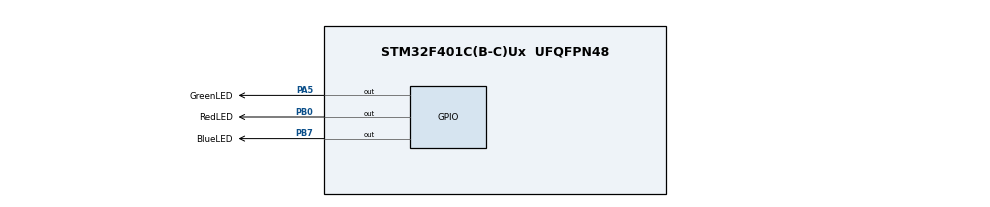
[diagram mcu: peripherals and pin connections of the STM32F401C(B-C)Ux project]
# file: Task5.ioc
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FREERTOS.Tasks01=defaultTask,24,128,StartDefaultTask,Default,NULL,Dynamic,NULL,NULL;FlashRedLEDTask,32,128,FlashRedLED,Default,NULL,Dynamic,NULL,NULL;FlashGreenLEDTa,24,128,FlashGreenLED,Default,NULL,Dynamic,NULL,NULL
Mcu.Family=STM32F4
Mcu.Name=STM32F401C(B-C)Ux
Mcu.Package=UFQFPN48
NVIC.PriorityGroup=NVIC_PRIORITYGROUP_4
PA13.Mode=Serial_Wire
PA13.Signal=SYS_JTMS-SWDIO
PA14.Mode=Serial_Wire
PA14.Signal=SYS_JTCK-SWCLK
PA5.GPIO_Label=GreenLED
PA5.Signal=GPIO_Output
PB0.GPIO_Label=RedLED
PB0.Signal=GPIO_Output
PB7.GPIO_Label=BlueLED
PB7.Signal=GPIO_Output
ProjectManager.HeapSize=0x200
ProjectManager.StackSize=0x400
ProjectManager.TargetToolchain=STM32CubeIDE
RCC.AHBFreq_Value=16000000
RCC.APB1Freq_Value=16000000
RCC.APB2Freq_Value=16000000
RCC.CortexFreq_Value=16000000
RCC.HSE_VALUE=25000000
RCC.HSI_VALUE=16000000
RCC.LSE_VALUE=32768
RCC.SYSCLKFreq_VALUE=16000000
RCC.VCOOutputFreq_Value=192000000
VP_FREERTOS_VS_CMSIS_V2.Mode=CMSIS_V2
board=custom

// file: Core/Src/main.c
/* USER CODE BEGIN Header */
/**
  ******************************************************************************
  * @file           : main.c
  * @brief          : Main program body
  ******************************************************************************
  */
/* USER CODE END Header */
#include "main.h"
#include "cmsis_os.h"

/* USER CODE BEGIN Includes */
#include "stm32f4xx_hal.h"
/* USER CODE END Includes */

osThreadId_t FlashGreenLEDTaskHandle;
osThreadId_t FlashRedLEDTaskHandle;

const osThreadAttr_t FlashGreenLEDTask_attributes = {
  .name = "FlashGreenLEDTask",
  .stack_size = 128 * 4,
  .priority = (osPriority_t) osPriorityNormal,
};
const osThreadAttr_t FlashRedLEDTask_attributes = {
  .name = "FlashRedLEDTask",
  .stack_size = 128 * 4,
  .priority = (osPriority_t) osPriorityAboveNormal,
};

/* USER CODE BEGIN PV */
volatile int start_flag = 1;
/* USER CODE END PV */

void SystemClock_Config(void);
static void MX_GPIO_Init(void);
void FlashGreenLED(void *argument);
void FlashRedLED(void *argument);
void AccessSharedData(void);

int main(void)
{
  HAL_Init();
  SystemClock_Config();
  MX_GPIO_Init();

  osKernelInitialize();
  FlashGreenLEDTaskHandle = osThreadNew(FlashGreenLED, NULL, &FlashGreenLEDTask_attributes);
  FlashRedLEDTaskHandle = osThreadNew(FlashRedLED, NULL, &FlashRedLEDTask_attributes);
  osKernelStart();

  while (1)
  {
    // Main loop
  }
}

void SystemClock_Config(void)
{
  /* Configure clock as needed */
}

static void MX_GPIO_Init(void)
{
  GPIO_InitTypeDef GPIO_InitStruct = {0};

  /* Enable GPIO Ports Clock */
  __HAL_RCC_GPIOA_CLK_ENABLE();
  __HAL_RCC_GPIOB_CLK_ENABLE();

  /* Configure GPIO pin for Green LED (PA5) */
  GPIO_InitStruct.Pin = GPIO_PIN_5;
  GPIO_InitStruct.Mode = GPIO_MODE_OUTPUT_PP;
  GPIO_InitStruct.Pull = GPIO_NOPULL;
  GPIO_InitStruct.Speed = GPIO_SPEED_FREQ_LOW;
  HAL_GPIO_Init(GPIOA, &GPIO_InitStruct);

  /* Configure GPIO pin for Red LED (PB0) and Blue LED (PB7) */
  GPIO_InitStruct.Pin = GPIO_PIN_0 | GPIO_PIN_7;
  HAL_GPIO_Init(GPIOB, &GPIO_InitStruct);
}

void FlashGreenLED(void *argument)
{
 for(;;)
  {
    HAL_GPIO_WritePin(GPIOA, GPIO_PIN_5, GPIO_PIN_SET);
    AccessSharedData();
    HAL_GPIO_WritePin(GPIOA, GPIO_PIN_5, GPIO_PIN_RESET);
    osDelay(500);
  }
}

void FlashRedLED(void *argument)
{
  for(;;)
  {
    HAL_GPIO_WritePin(GPIOB, GPIO_PIN_0, GPIO_PIN_SET);
    AccessSharedData();
    HAL_GPIO_WritePin(GPIOB, GPIO_PIN_0, GPIO_PIN_RESET);
    osDelay(100);
  }
}

/**
  * @brief Access shared data and check for collisions.
  * @retval None
  */
void AccessSharedData(void)
{
    if (start_flag == 1)
    {
        start_flag = 0;
    }
    else
    {
        HAL_GPIO_WritePin(GPIOB, GPIO_PIN_7, GPIO_PIN_SET);
    }

    osDelay(500);

    start_flag = 1;

    HAL_GPIO_WritePin(GPIOB, GPIO_PIN_7, GPIO_PIN_RESET);
}

void Error_Handler(void) {
  __disable_irq();
  while (1) {
  }
}
